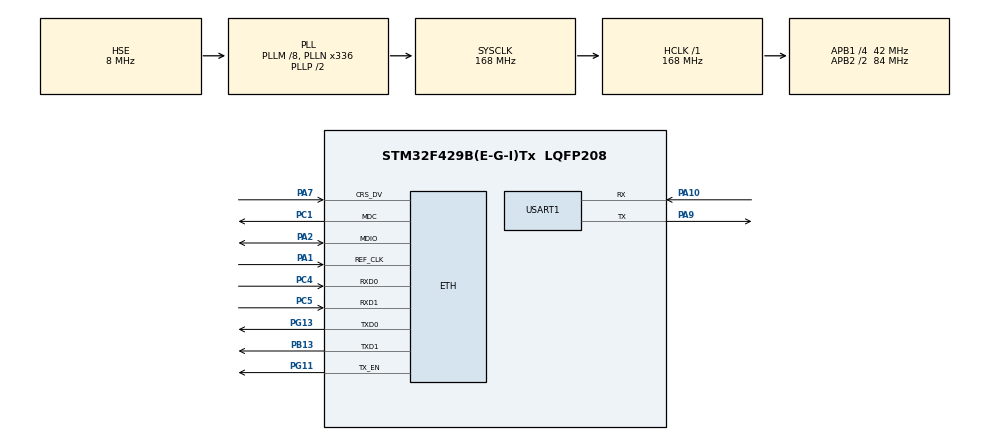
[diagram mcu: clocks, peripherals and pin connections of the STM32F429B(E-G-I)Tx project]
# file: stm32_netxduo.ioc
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ETH.MediaInterface=HAL_ETH_RMII_MODE
ETH.RxMode=ETH_RXINTERRUPT_MODE
Mcu.Family=STM32F4
Mcu.Name=STM32F429B(E-G-I)Tx
Mcu.Package=LQFP208
NVIC.ETH_IRQn=true\:2\:0\:true\:false\:true\:false\:true\:true\:true
NVIC.PriorityGroup=NVIC_PRIORITYGROUP_4
NVIC.TIM1_UP_TIM10_IRQn=true\:14\:0\:true\:false\:true\:false\:false\:true\:true
NVIC.TimeBase=TIM1_UP_TIM10_IRQn
NVIC.TimeBaseIP=TIM1
NVIC.USART1_IRQn=true\:13\:0\:true\:false\:true\:false\:true\:true\:true
PA1.Mode=RMII
PA1.Signal=ETH_REF_CLK
PA10.Mode=Asynchronous
PA10.Signal=USART1_RX
PA13.Mode=Serial_Wire
PA13.Signal=SYS_JTMS-SWDIO
PA14.Mode=Serial_Wire
PA14.Signal=SYS_JTCK-SWCLK
PA2.Mode=RMII
PA2.Signal=ETH_MDIO
PA7.Mode=RMII
PA7.Signal=ETH_CRS_DV
PA9.Mode=Asynchronous
PA9.Signal=USART1_TX
PB13.Mode=RMII
PB13.Signal=ETH_TXD1
PC1.Mode=RMII
PC1.Signal=ETH_MDC
PC4.Mode=RMII
PC4.Signal=ETH_RXD0
PC5.Mode=RMII
PC5.Signal=ETH_RXD1
PG11.Mode=RMII
PG11.Signal=ETH_TX_EN
PG13.Mode=RMII
PG13.Signal=ETH_TXD0
PH0/OSC_IN.Mode=HSE-External-Oscillator
PH0/OSC_IN.Signal=RCC_OSC_IN
PH1/OSC_OUT.Mode=HSE-External-Oscillator
PH1/OSC_OUT.Signal=RCC_OSC_OUT
ProjectManager.HeapSize=0x200
ProjectManager.StackSize=0x400
ProjectManager.TargetToolchain=STM32CubeIDE
RCC.48MHZClocksFreq_Value=84000000
RCC.AHBFreq_Value=168000000
RCC.APB1CLKDivider=RCC_HCLK_DIV4
RCC.APB1Freq_Value=42000000
RCC.APB1TimFreq_Value=84000000
RCC.APB2CLKDivider=RCC_HCLK_DIV2
RCC.APB2Freq_Value=84000000
RCC.APB2TimFreq_Value=168000000
RCC.CortexFreq_Value=168000000
RCC.HCLKFreq_Value=168000000
RCC.HSE_VALUE=8000000
RCC.HSI_VALUE=16000000
RCC.LSE_VALUE=32768
RCC.PLLM=8
RCC.PLLN=336
RCC.PLLSourceVirtual=RCC_PLLSOURCE_HSE
RCC.SYSCLKFreq_VALUE=168000000
RCC.SYSCLKSource=RCC_SYSCLKSOURCE_PLLCLK
RCC.VCOOutputFreq_Value=336000000
STMicroelectronics.X-CUBE-AZRTOS-F4.1.1.0.InterfacesCcNetworkJjEthernetOoInterface=true
STMicroelectronics.X-CUBE-AZRTOS-F4.1.1.0.InterfacesCcNetworkJjEthernetOoPhyOoInterface=LAN8742IiPhyIiInterface
STMicroelectronics.X-CUBE-AZRTOS-F4.1.1.0.NX_APP_MEM_POOL_SIZE=30*1024
STMicroelectronics.X-CUBE-AZRTOS-F4.1.1.0.NX_AUTO_IP_DEBUG=false
STMicroelectronics.X-CUBE-AZRTOS-F4.1.1.0.NX_ENABLE_INTERFACE_CAPABILITY=true
STMicroelectronics.X-CUBE-AZRTOS-F4.1.1.0.NetXDuoCcNetworkJjNetXDuoJjAddonsOoAutoIP=true
STMicroelectronics.X-CUBE-AZRTOS-F4.1.1.0.NetXDuoCcNetworkJjNetXDuoJjAddonsOoDHCPOoClient=true
STMicroelectronics.X-CUBE-AZRTOS-F4.1.1.0.NetXDuoCcNetworkJjNetXDuoJjNXOoCore=true
STMicroelectronics.X-CUBE-AZRTOS-F4.1.1.0.STM32CubeIiBSPIiComponentsCcBoardOoPartJjETHPhyJjLAN8742=true
STMicroelectronics.X-CUBE-AZRTOS-F4.1.1.0.TX_DISABLE_NOTIFY_CALLBACKS=0
STMicroelectronics.X-CUBE-AZRTOS-F4.1.1.0.TX_ENABLE_EXECUTION_CHANGE_NOTIFY=1
STMicroelectronics.X-CUBE-AZRTOS-F4.1.1.0.ThreadXCcRTOSJjThreadXJjCore=true
STMicroelectronics.X-CUBE-AZRTOS-F4.1.1.0.ThreadXCcRTOSJjThreadXJjTraceXOosupport=true
STMicroelectronics.X-CUBE-AZRTOS-F4.1.1.0_IsAnAzureRtosMw=true
USART1.VirtualMode=VM_ASYNC
VP_STMicroelectronics.X-CUBE-AZRTOS-F4_VS_BoardOoPartJjSTM32CubeIiBSPIiComponents_1.1.0_1.1.0.Mode=BoardOoPartJjSTM32CubeIiBSPIiComponents
VP_STMicroelectronics.X-CUBE-AZRTOS-F4_VS_NetworkJjInterfaces_2.1.0_1.1.0.Mode=NetworkJjInterfaces
VP_STMicroelectronics.X-CUBE-AZRTOS-F4_VS_NetworkJjNetXDuo_6.1.10_1.1.0.Mode=NetworkJjNetXDuo
VP_STMicroelectronics.X-CUBE-AZRTOS-F4_VS_RTOSJjThreadX_6.1.10_1.1.0.Mode=RTOSJjThreadX
VP_SYS_VS_tim1.Mode=TIM1
board=custom

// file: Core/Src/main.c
/* USER CODE BEGIN Header */
/**
  ******************************************************************************
  * @file           : main.c
  * @brief          : Main program body
  ******************************************************************************
  * @attention
  *
  * Copyright (c) 2023 STMicroelectronics.
  * All rights reserved.
  *
  * This software is licensed under terms that can be found in the LICENSE file
  * in the root directory of this software component.
  * If no LICENSE file comes with this software, it is provided AS-IS.
  *
  ******************************************************************************
  */
/* USER CODE END Header */
#include "app_threadx.h"
#include "main.h"
#include "eth.h"
#include "usart.h"
#include "gpio.h"

/* USER CODE BEGIN Includes */
#include "bsp_fmc_io.h"
#include "bsp_led.h"
#include <stdio.h>
/* USER CODE END Includes */

void SystemClock_Config(void);

int main(void)
{

  /* MCU Configuration--------------------------------------------------------*/

  /* Reset of all peripherals, Initializes the Flash interface and the Systick. */
  HAL_Init();

  /* Configure the system clock */
  SystemClock_Config();

  /* Initialize all configured peripherals */
  MX_GPIO_Init();
  MX_ETH_Init();
  MX_USART1_UART_Init();
  /* USER CODE BEGIN 2 */
  bsp_InitExtIO();    /* 初始化扩展IO */
	bsp_InitLed();    	/* 初始化LED */

  printf("welcome internet world\r\n");
  /* USER CODE END 2 */

  MX_ThreadX_Init();

  /* We should never get here as control is now taken by the scheduler */
  /* Infinite loop */
  while (1)
  {

  }
}

void SystemClock_Config(void)
{
  RCC_OscInitTypeDef RCC_OscInitStruct = {0};
  RCC_ClkInitTypeDef RCC_ClkInitStruct = {0};

  /** Configure the main internal regulator output voltage
  */
  __HAL_RCC_PWR_CLK_ENABLE();
  __HAL_PWR_VOLTAGESCALING_CONFIG(PWR_REGULATOR_VOLTAGE_SCALE1);

  /** Initializes the RCC Oscillators according to the specified parameters
  * in the RCC_OscInitTypeDef structure.
  */
  RCC_OscInitStruct.OscillatorType = RCC_OSCILLATORTYPE_HSE;
  RCC_OscInitStruct.HSEState = RCC_HSE_ON;
  RCC_OscInitStruct.PLL.PLLState = RCC_PLL_ON;
  RCC_OscInitStruct.PLL.PLLSource = RCC_PLLSOURCE_HSE;
  RCC_OscInitStruct.PLL.PLLM = 8;
  RCC_OscInitStruct.PLL.PLLN = 336;
  RCC_OscInitStruct.PLL.PLLP = RCC_PLLP_DIV2;
  RCC_OscInitStruct.PLL.PLLQ = 4;
  if (HAL_RCC_OscConfig(&RCC_OscInitStruct) != HAL_OK)
  {
    Error_Handler();
  }

  /** Initializes the CPU, AHB and APB buses clocks
  */
  RCC_ClkInitStruct.ClockType = RCC_CLOCKTYPE_HCLK|RCC_CLOCKTYPE_SYSCLK
                              |RCC_CLOCKTYPE_PCLK1|RCC_CLOCKTYPE_PCLK2;
  RCC_ClkInitStruct.SYSCLKSource = RCC_SYSCLKSOURCE_PLLCLK;
  RCC_ClkInitStruct.AHBCLKDivider = RCC_SYSCLK_DIV1;
  RCC_ClkInitStruct.APB1CLKDivider = RCC_HCLK_DIV4;
  RCC_ClkInitStruct.APB2CLKDivider = RCC_HCLK_DIV2;

  if (HAL_RCC_ClockConfig(&RCC_ClkInitStruct, FLASH_LATENCY_5) != HAL_OK)
  {
    Error_Handler();
  }
}

void HAL_TIM_PeriodElapsedCallback(TIM_HandleTypeDef *htim)
{
  if (htim->Instance == TIM1) {
    HAL_IncTick();
  }
  /* USER CODE BEGIN Callback 1 */
  static uint32_t count = 0;
  count++;
  if (count > 300)
  {
    bsp_LedToggle(2);
    count = 0;
  }
  /* USER CODE END Callback 1 */
}

void Error_Handler(void)
{
  __disable_irq();
  while (1)
  {
  }
}
